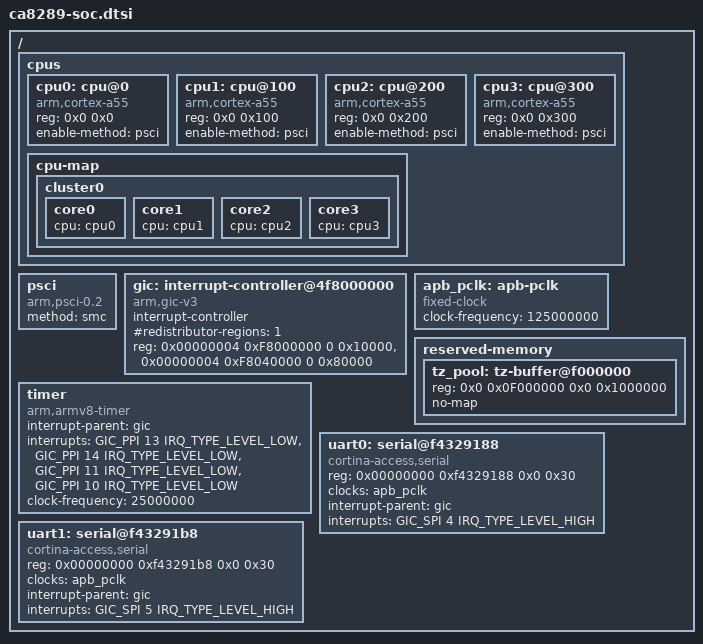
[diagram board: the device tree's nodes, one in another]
// SPDX-License-Identifier: GPL-2.0
/*
 * dts file for Cortina Access CA8289 SoC
 *
 * Copyright (C) 2026, Cortina Access Inc.
 */

#include <dt-bindings/interrupt-controller/arm-gic.h>
#include <dt-bindings/interrupt-controller/irq.h>

/ {
	cpus {
		#address-cells = <2>;
		#size-cells = <0>;

		cpu0: cpu@0 {
			compatible = "arm,cortex-a55", "arm,armv8";
			device_type = "cpu";
			reg = <0x0 0x0>;
			enable-method = "psci";
		};
		cpu1: cpu@100 {
			compatible = "arm,cortex-a55", "arm,armv8";
			device_type = "cpu";
			reg = <0x0 0x100>;
			enable-method = "psci";
		};
		cpu2: cpu@200 {
			compatible = "arm,cortex-a55", "arm,armv8";
			device_type = "cpu";
			reg = <0x0 0x200>;
			enable-method = "psci";
		};
		cpu3: cpu@300 {
			compatible = "arm,cortex-a55", "arm,armv8";
			device_type = "cpu";
			reg = <0x0 0x300>;
			enable-method = "psci";
		};
		cpu-map {
			cluster0 {
				core0 {
					cpu = <&cpu0>;
				};
				core1 {
					cpu = <&cpu1>;
				};
				core2 {
					cpu = <&cpu2>;
				};
				core3 {
					cpu = <&cpu3>;
				};
			};
		};
	};

	psci {
		compatible = "arm,psci-0.2";
		method = "smc";
	};

	gic: interrupt-controller@4f8000000 {
		compatible = "arm,gic-v3";
		#interrupt-cells = <3>;
		interrupt-controller;
		#redistributor-regions = <1>;
		reg = <0x00000004 0xF8000000 0 0x10000>,
		      <0x00000004 0xF8040000 0 0x80000>;
	};

	apb_pclk: apb-pclk {
		compatible = "fixed-clock";
		#clock-cells = <0>;
		clock-frequency = <125000000>;
	};

	reserved-memory {
		#address-cells = <2>;
		#size-cells = <2>;
		ranges;

		/* TrustZone reserved region; must not be mapped by the kernel */
		tz_pool: tz-buffer@f000000 {
			reg = <0x0 0x0F000000 0x0 0x1000000>;
			no-map;
		};
	};

	/* See Documentation/devicetree/bindings/timer/arm,arch_timer.yaml */
	timer {
		compatible = "arm,armv8-timer";
		interrupt-parent = <&gic>;
		interrupts = <GIC_PPI 13 IRQ_TYPE_LEVEL_LOW>,
			     <GIC_PPI 14 IRQ_TYPE_LEVEL_LOW>,
			     <GIC_PPI 11 IRQ_TYPE_LEVEL_LOW>,
			     <GIC_PPI 10 IRQ_TYPE_LEVEL_LOW>;
		clock-frequency = <25000000>;
	};

	uart0: serial@f4329188 {
		device_type = "serial";
		compatible = "cortina-access,serial";
		reg = <0x00000000 0xf4329188 0x0 0x30>;
		clocks = <&apb_pclk>;
		interrupt-parent = <&gic>;
		interrupts = <GIC_SPI 4 IRQ_TYPE_LEVEL_HIGH>;
	};

	uart1: serial@f43291b8 {
		device_type = "serial";
		compatible = "cortina-access,serial";
		reg = <0x00000000 0xf43291b8 0x0 0x30>;
		clocks = <&apb_pclk>;
		interrupt-parent = <&gic>;
		interrupts = <GIC_SPI 5 IRQ_TYPE_LEVEL_HIGH>;
	};
};
